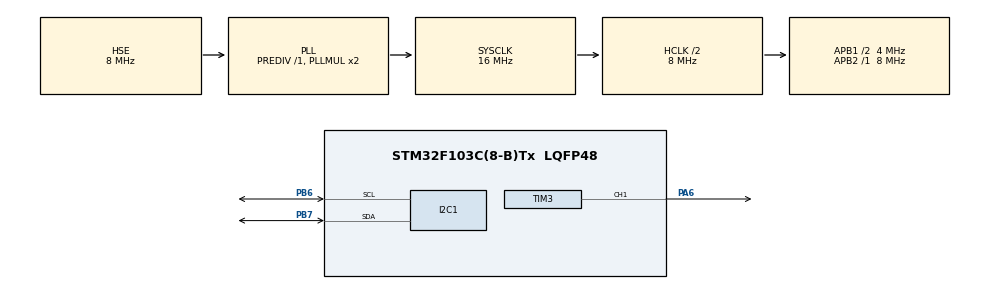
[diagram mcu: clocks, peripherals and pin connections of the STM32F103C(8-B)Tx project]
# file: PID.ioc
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Mcu.Family=STM32F1
Mcu.Name=STM32F103C(8-B)Tx
Mcu.Package=LQFP48
NVIC.PriorityGroup=NVIC_PRIORITYGROUP_4
NVIC.TIM2_IRQn=true\:0\:0\:false\:false\:true\:true\:true\:true
PA13.Mode=Serial_Wire
PA13.Signal=SYS_JTMS-SWDIO
PA14.Mode=Serial_Wire
PA14.Signal=SYS_JTCK-SWCLK
PA6.Signal=S_TIM3_CH1
PB6.Mode=I2C
PB6.Signal=I2C1_SCL
PB7.Mode=I2C
PB7.Signal=I2C1_SDA
PC14-OSC32_IN.Mode=LSE-External-Oscillator
PC14-OSC32_IN.Signal=RCC_OSC32_IN
PC15-OSC32_OUT.Mode=LSE-External-Oscillator
PC15-OSC32_OUT.Signal=RCC_OSC32_OUT
PD0-OSC_IN.Mode=HSE-External-Oscillator
PD0-OSC_IN.Signal=RCC_OSC_IN
PD1-OSC_OUT.Mode=HSE-External-Oscillator
PD1-OSC_OUT.Signal=RCC_OSC_OUT
ProjectManager.HeapSize=0x200
ProjectManager.StackSize=0x400
ProjectManager.TargetToolchain=MDK-ARM V5.32
RCC.AHBCLKDivider=RCC_SYSCLK_DIV2
RCC.AHBFreq_Value=8000000
RCC.APB1CLKDivider=RCC_HCLK_DIV2
RCC.APB1Freq_Value=4000000
RCC.APB1TimFreq_Value=8000000
RCC.APB2Freq_Value=8000000
RCC.APB2TimFreq_Value=8000000
RCC.HCLKFreq_Value=8000000
RCC.PLLSourceVirtual=RCC_PLLSOURCE_HSE
RCC.SYSCLKFreq_VALUE=16000000
RCC.SYSCLKSource=RCC_SYSCLKSOURCE_PLLCLK
RCC.USBFreq_Value=16000000
SH.S_TIM3_CH1.0=TIM3_CH1,PWM Generation1 CH1
TIM2.Period=9999
TIM2.Prescaler=7
TIM3.Channel-PWM\ Generation1\ CH1=TIM_CHANNEL_1
TIM3.Period=19999
TIM3.Prescaler=7
VP_TIM2_VS_ClockSourceINT.Mode=Internal
VP_TIM3_VS_ClockSourceINT.Mode=Internal
board=custom

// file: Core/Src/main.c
/* USER CODE BEGIN Header */
/**
  ******************************************************************************
  * @file           : main.c
  * @brief          : Main program body
  ******************************************************************************
  * @attention
  *
  * Copyright (c) 2026 STMicroelectronics.
  * All rights reserved.
  *
  * This software is licensed under terms that can be found in the LICENSE file
  * in the root directory of this software component.
  * If no LICENSE file comes with this software, it is provided AS-IS.
  *
  ******************************************************************************
  */
/* USER CODE END Header */
#include "main.h"
#include "i2c.h"
#include "tim.h"
#include "gpio.h"

/* USER CODE BEGIN Includes */
#include "math.h"
#include "pid.h"
/* USER CODE END Includes */

void SystemClock_Config(void);

/* USER CODE BEGIN 0 */
volatile  uint16_t timer1_flag = 0;
volatile  uint16_t timer1_counter = 0;

void SetTimer(uint16_t duration){
	timer1_flag = 0;
	timer1_counter = duration;
}

void RunTimer(){
	if(timer1_counter > 0){
		timer1_counter --;
		if (timer1_counter == 0){
			timer1_flag = 1;
		}
	}
}

volatile uint8_t mpu_update_flag = 0;

void HAL_TIM_PeriodElapsedCallback(TIM_HandleTypeDef *htim){
	//RunTimer();
	if (htim->Instance == TIM2)
	{
			mpu_update_flag = 1;
	}
}

void Servo_Init()
{
	HAL_TIM_PWM_Start(&htim3, TIM_CHANNEL_1);
}

void Servo_Write(uint8_t angle)
{
	// ccr = (max-min) * angle / 180 + min
	// servo sg90: min 0.5micros, max 2500micros
	uint16_t pulse = (((2500 - 500) * angle) / 180) + 500;
	__HAL_TIM_SetCompare(&htim3, TIM_CHANNEL_1, pulse);
}

#define 	MPU6050_ADDR		(0x68 << 1)
#define 	RAD_TO_DEG 			57.295779513082320876798154814105f
#define 	ALPHA 					0.96f

float SensitivityA 	= 16384.0f;
float SensitivityG	= 131.0f;

float gx, gy, gz;
float ax, ay, az;

float pitch = 0.0f;
float roll = 0.0f;
float yaw = 0.0f;

uint32_t prev_time = 0;

void MPU6050_Init();
void MPU6050_ReadAccel();
void MPU6050_ReadGyro();
void MPU6050_ReadAngle();
void MPU6050_CalculateAngle(float ax, float ay, float az, float gx, float gy, float gz);

void MPU6050_Init(){
	uint8_t check, data;

	HAL_I2C_Mem_Read(&hi2c1, MPU6050_ADDR, 0x75, 1, &check, 1, 1000);

	if(check == 0x68){
		data = 0x00;
		HAL_I2C_Mem_Write(&hi2c1, MPU6050_ADDR, 0x6B, 1, &data, 1, 1000);
		data = 0x07;
		HAL_I2C_Mem_Write(&hi2c1, MPU6050_ADDR, 0x19, 1, &data, 1, 1000);
		data = 0x00;
		HAL_I2C_Mem_Write(&hi2c1, MPU6050_ADDR, 0x1B, 1, &data, 1, 1000);
		data = 0x00;
		HAL_I2C_Mem_Write(&hi2c1, MPU6050_ADDR, 0x1C, 1, &data, 1, 1000);
		data = 0x03;
		HAL_I2C_Mem_Write(&hi2c1, MPU6050_ADDR, 0x1A, 1, &data, 1, 1000);
	}

}

void MPU6050_ReadAccel(){
	uint8_t data[6];
	HAL_I2C_Mem_Read(&hi2c1, MPU6050_ADDR, 0x3B, 1, data, 6, 1000);

	int16_t raw_ax = (int16_t)(data[0] << 8 | data[1]);
  int16_t raw_ay = (int16_t)(data[2] << 8 | data[3]);
  int16_t raw_az = (int16_t)(data[4] << 8 | data[5]);

  ax = (float)raw_ax / SensitivityA;
  ay = (float)raw_ay / SensitivityA;
  az = (float)raw_az / SensitivityA;
}

void MPU6050_ReadGyro(){
	uint8_t data[6];
	HAL_I2C_Mem_Read(&hi2c1, MPU6050_ADDR, 0x43, 1, data, 6, 1000);

	int16_t raw_gx = (int16_t)(data[0] << 8 | data[1]);
  int16_t raw_gy = (int16_t)(data[2] << 8 | data[3]);
  int16_t raw_gz = (int16_t)(data[4] << 8 | data[5]);

  gx = (float)raw_gx / SensitivityG;
  gy = (float)raw_gy / SensitivityG;
  gz = (float)raw_gz / SensitivityG;
}

void MPU6050_CalculateAngle(float ax, float ay, float az, float gx, float gy, float gz)
{
	uint32_t current_time = HAL_GetTick();

	if (prev_time == 0) {
		prev_time = current_time;
		return;
	}

	float dt = (float)(current_time - prev_time) / 1000.0f;
	prev_time = current_time;

	if (dt <= 0.0f) return;

	float roll_accel  = atan2f(ay, sqrtf(ax * ax + az * az)) * RAD_TO_DEG;
	float pitch_accel = atan2f(ax, sqrtf(ay * ay + az * az)) * RAD_TO_DEG;

	roll  = ALPHA * (roll  + gx * dt) + (1.0f - ALPHA) * roll_accel;
	pitch = ALPHA * (pitch + gy * dt) + (1.0f - ALPHA) * pitch_accel;

	yaw += gz * dt;
}

PID_HandleTypeDef anglePid;

/* USER CODE END 0 */

int main(void)
{

  /* MCU Configuration--------------------------------------------------------*/

  /* Reset of all peripherals, Initializes the Flash interface and the Systick. */
  HAL_Init();

  /* Configure the system clock */
  SystemClock_Config();

  /* Initialize all configured peripherals */
  MX_GPIO_Init();
  MX_TIM2_Init();
  MX_I2C1_Init();
  MX_TIM3_Init();
  /* USER CODE BEGIN 2 */
	// LUU Y: pid_output la DO LECH (us) quanh tam servo (1500us = 90 do co khi),
	// khong phai gia tri goc servo can toi. Vi vay setpoint phai la gia tri "pitch"
	// khi tay/be mat cam bien o vi tri can giu (thuong ~0 do neu de PHANG), chu KHONG
	// phai 90.0f. Hay nap thu, in gia tri "pitch" qua UART/breakpoint luc de phang de
	// xac nhan, roi chinh lai so nay cho dung setup cua ban.
	PID_Init(&anglePid,
					 2.1f, 0.4f, 0.2f,   // Kp, Ki, Kd — chỉnh lại theo thực tế
					 0.0f,               // setpoint: gia tri pitch mong muon giu (XEM LUU Y TREN)
					 -400.0f, 400.0f,    // gioi han output (us lech quanh tam)
					 0.01f);             // Ts = 10ms, khop chu ky ngat TIM2

	Servo_Init();
	__HAL_TIM_SET_COMPARE(&htim3, TIM_CHANNEL_1, 1500); // dat servo ve giua (90 do) truoc
	HAL_TIM_Base_Start_IT(&htim2); // bat dau ngat 100Hz
	MPU6050_Init();

	/* ======================================================= */
  /* USER CODE END 2 */

  /* Infinite loop */
  /* USER CODE BEGIN WHILE */
	//HAL_GPIO_WritePin(GPIOA, GPIO_PIN_5, 0);
	//uint8_t duration = 2;
	//SetTimer(duration);
  while (1)
  {
		/*
		if(timer1_flag == 1){
			SetTimer(duration);
			HAL_GPIO_TogglePin(GPIOA, GPIO_PIN_5);
		}
		*/

    /* USER CODE END WHILE */

    /* USER CODE BEGIN 3 */

		if (mpu_update_flag)
    {
        mpu_update_flag = 0;
				int32_t pulse;
        float current_angle, pid_output;

        MPU6050_ReadAccel();
				MPU6050_ReadGyro();
				MPU6050_CalculateAngle(ax, ay, az, gx, gy, gz);

        current_angle = pitch;     // <-- chon truc phan hoi phu hop (Pitch/Roll/Yaw)

        pid_output = PID_Compute(&anglePid, current_angle);

				// pid_output la do lech (us) quanh tam servo, KHONG phai goc 0-180
				// nen khong dung Servo_Write() (ham do nhan goc do) ma set CCR truc tiep
				pulse = 1500 + (int32_t)pid_output;

				if (pulse > 2500) pulse = 2500;   // gioi han an toan SG90
				if (pulse < 500)  pulse = 500;

				__HAL_TIM_SetCompare(&htim3, TIM_CHANNEL_1, (uint16_t)pulse);
		}
}
  /* USER CODE END 3 */
}

void SystemClock_Config(void)
{
  RCC_OscInitTypeDef RCC_OscInitStruct = {0};
  RCC_ClkInitTypeDef RCC_ClkInitStruct = {0};

  /** Initializes the RCC Oscillators according to the specified parameters
  * in the RCC_OscInitTypeDef structure.
  */
  RCC_OscInitStruct.OscillatorType = RCC_OSCILLATORTYPE_HSE;
  RCC_OscInitStruct.HSEState = RCC_HSE_ON;
  RCC_OscInitStruct.HSEPredivValue = RCC_HSE_PREDIV_DIV1;
  RCC_OscInitStruct.HSIState = RCC_HSI_ON;
  RCC_OscInitStruct.PLL.PLLState = RCC_PLL_ON;
  RCC_OscInitStruct.PLL.PLLSource = RCC_PLLSOURCE_HSE;
  RCC_OscInitStruct.PLL.PLLMUL = RCC_PLL_MUL2;
  if (HAL_RCC_OscConfig(&RCC_OscInitStruct) != HAL_OK)
  {
    Error_Handler();
  }

  /** Initializes the CPU, AHB and APB buses clocks
  */
  RCC_ClkInitStruct.ClockType = RCC_CLOCKTYPE_HCLK|RCC_CLOCKTYPE_SYSCLK
                              |RCC_CLOCKTYPE_PCLK1|RCC_CLOCKTYPE_PCLK2;
  RCC_ClkInitStruct.SYSCLKSource = RCC_SYSCLKSOURCE_PLLCLK;
  RCC_ClkInitStruct.AHBCLKDivider = RCC_SYSCLK_DIV2;
  RCC_ClkInitStruct.APB1CLKDivider = RCC_HCLK_DIV2;
  RCC_ClkInitStruct.APB2CLKDivider = RCC_HCLK_DIV1;

  if (HAL_RCC_ClockConfig(&RCC_ClkInitStruct, FLASH_LATENCY_0) != HAL_OK)
  {
    Error_Handler();
  }
}

void Error_Handler(void)
{
  __disable_irq();
  while (1)
  {
  }
}
